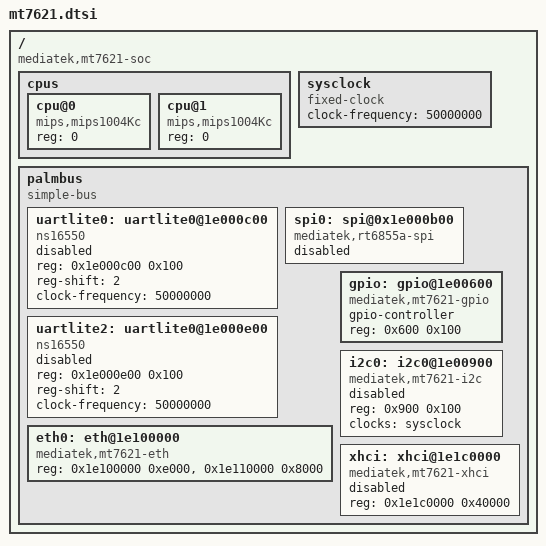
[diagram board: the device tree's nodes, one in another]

#include "skeleton.dtsi"

/ {
	compatible = "mediatek,mt7621-soc";

	#address-cells = <1>;
	#size-cells = <1>;

	cpus {
		#address-cells = <1>;
		#size-cells = <0>;

		cpu@0 {
			device_type = "cpu";
			compatible = "mips,mips1004Kc";
			reg = <0>;
		};

		cpu@1 {
			device_type = "cpu";
			compatible = "mips,mips1004Kc";
			reg = <0>;
		};
	};

	sysclock: sysclock {
		#clock-cells = <0>;
		compatible = "fixed-clock";
		clock-frequency = <50000000>;
	};

	palmbus {
		compatible = "simple-bus";
		ranges;

		#address-cells = <1>;
		#size-cells = <1>;

		uartlite0: uartlite0@1e000c00 {
			compatible = "ns16550";
			reg = <0x1e000c00 0x100>;
			reg-shift = <2>;
			clock-frequency = <50000000>;

			status = "disabled";
		};

		uartlite2: uartlite0@1e000e00 {
			compatible = "ns16550";
			reg = <0x1e000e00 0x100>;
			reg-shift = <2>;
			clock-frequency = <50000000>;

			status = "disabled";
		};

		spi0: spi@0x1e000b00 {
			compatible = "mediatek,rt6855a-spi";

			status = "disabled";

			#address-cells = <1>;
			#size-cells = <0>;
		};

		eth0: eth@1e100000 {
			compatible = "mediatek,mt7621-eth";
			reg = <0x1e100000 0xe000>,
				<0x1e110000 0x8000>;
			reg-names = "fe", "gmac";

			status = "okay";

			#address-cells = <1>;
			#size-cells = <0>;
		};

		gpio: gpio@1e00600 {
			#gpio-cells = <2>;
			compatible = "mediatek,mt7621-gpio";
			gpio-controller;
			reg = <0x600 0x100>;
			status = "okay";
		};

		i2c0: i2c0@1e00900 {
			compatible = "mediatek,mt7621-i2c";
			reg = <0x900 0x100>;

			clocks = <&sysclock>;

			#address-cells = <1>;
			#size-cells = <0>;

			status = "disabled";
		};
		xhci: xhci@1e1c0000 {
			compatible = "mediatek,mt7621-xhci";
			reg = <0x1e1c0000 0x40000>;

			status = "disabled";

			#address-cells = <1>;
			#size-cells = <0>;
		};

	};
};
